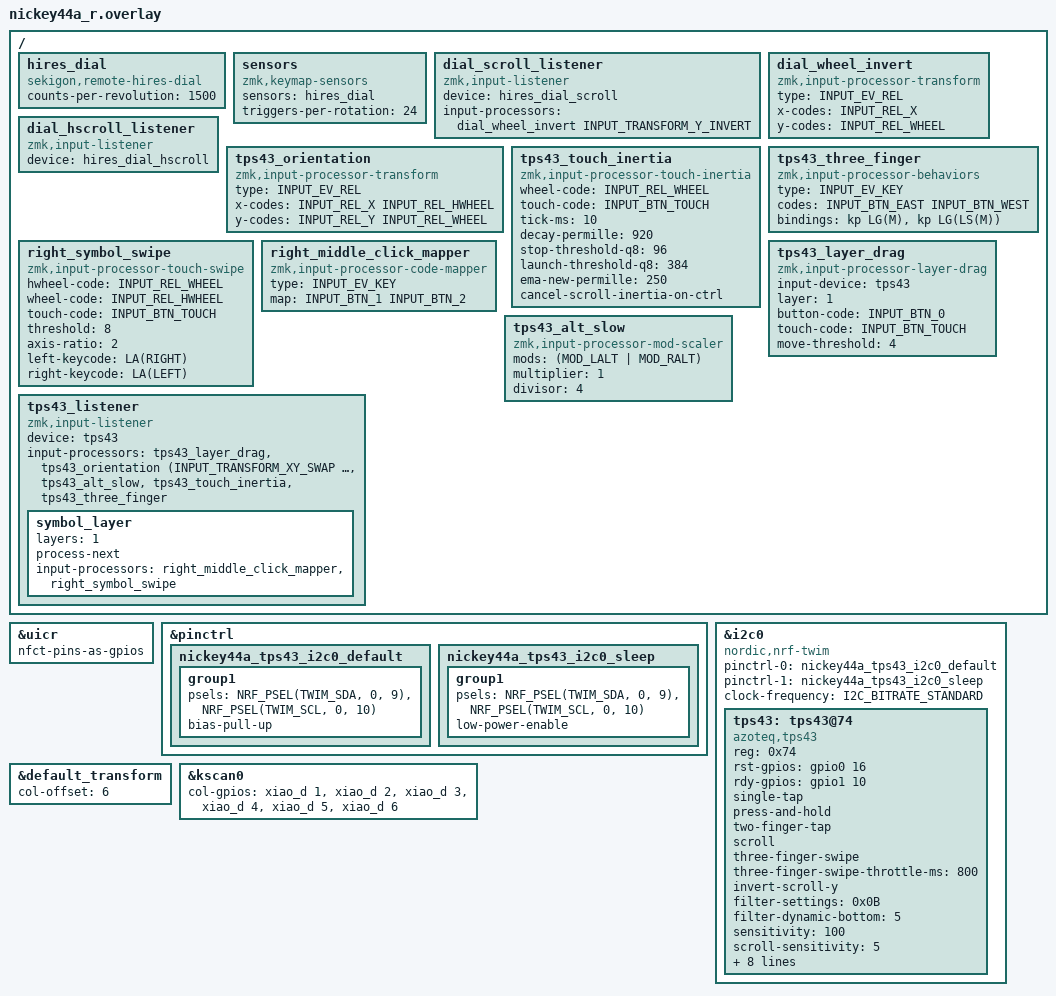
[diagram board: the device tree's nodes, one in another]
#include "nickey44a.dtsi"
#include <input/processors.dtsi>
#include <dt-bindings/pinctrl/nrf-pinctrl.h>
#include <dt-bindings/zmk/input_transform.h>
#include <dt-bindings/zmk/keys.h>
#include <zephyr/dt-bindings/input/input-event-codes.h>

/*
 * TPS43 FPC breakout wiring:
 *   SDA = XIAO NFC1/P0.09
 *   SCL = XIAO NFC2/P0.10
 *   RDY = XIAO P1.10
 *   NRST = XIAO P0.16
 */

&uicr {
    nfct-pins-as-gpios;
};

&pinctrl {
    nickey44a_tps43_i2c0_default: nickey44a_tps43_i2c0_default {
        group1 {
            psels = <NRF_PSEL(TWIM_SDA, 0, 9)>,
                    <NRF_PSEL(TWIM_SCL, 0, 10)>;
            /* The TPS43 breakout has no I2C pull-up resistors. */
            bias-pull-up;
        };
    };

    nickey44a_tps43_i2c0_sleep: nickey44a_tps43_i2c0_sleep {
        group1 {
            psels = <NRF_PSEL(TWIM_SDA, 0, 9)>,
                    <NRF_PSEL(TWIM_SCL, 0, 10)>;
            low-power-enable;
        };
    };
};

/ {
    /* Left-half high-resolution dial (sekigon hires-dial-module). The real
     * PAT9125 sensor sits on the left peripheral; this virtual node receives
     * its rotation over the split link. counts-per-revolution must match the
     * left overlay. */
    hires_dial: hires_dial {
        compatible = "sekigon,remote-hires-dial";
        counts-per-revolution = <1500>;
    };

    sensors: sensors {
        compatible = "zmk,keymap-sensors";
        sensors = <&hires_dial>;
        /* Key-sending layers (FUNC_NUM volume, ARROW tab switch): 24 steps per turn. */
        triggers-per-rotation = <24>;
    };

    /* BASE: dial = vertical wheel. The scroll behavior reports on its own
     * device; this listener sends it to the host. Clockwise (positive counts)
     * becomes a negative wheel = scroll down. */
    dial_scroll_listener: dial_scroll_listener {
        compatible = "zmk,input-listener";
        device = <&hires_dial_scroll>;
        input-processors = <&dial_wheel_invert INPUT_TRANSFORM_Y_INVERT>;
    };

    dial_wheel_invert: dial_wheel_invert {
        compatible = "zmk,input-processor-transform";
        #input-processor-cells = <1>;
        type = <INPUT_EV_REL>;
        x-codes = <INPUT_REL_X>;
        y-codes = <INPUT_REL_WHEEL>;
    };

    /* SYMBOL: dial = horizontal wheel. Clockwise (positive counts) is a
     * positive HWHEEL = scroll right. */
    dial_hscroll_listener: dial_hscroll_listener {
        compatible = "zmk,input-listener";
        device = <&hires_dial_hscroll>;
    };

    tps43_orientation: tps43_orientation {
        compatible = "zmk,input-processor-transform";
        #input-processor-cells = <1>;
        type = <INPUT_EV_REL>;
        x-codes = <INPUT_REL_X INPUT_REL_HWHEEL>;
        y-codes = <INPUT_REL_Y INPUT_REL_WHEEL>;
    };

    tps43_touch_inertia: tps43_touch_inertia {
        compatible = "zmk,input-processor-touch-inertia";
        #input-processor-cells = <0>;
        wheel-code = <INPUT_REL_WHEEL>;
        touch-code = <INPUT_BTN_TOUCH>;
        tick-ms = <10>;
        decay-permille = <920>;
        stop-threshold-q8 = <96>;
        launch-threshold-q8 = <384>;
        ema-new-permille = <250>;
        cancel-scroll-inertia-on-ctrl;
    };

    /* Right pad three-finger swipe. The driver reports it in controller
     * coordinates, before the orientation transform below: physical up is
     * BTN_EAST and physical down is BTN_WEST. Left/right are unmapped. */
    tps43_three_finger: tps43_three_finger {
        compatible = "zmk,input-processor-behaviors";
        #input-processor-cells = <0>;
        type = <INPUT_EV_KEY>;
        codes = <INPUT_BTN_EAST INPUT_BTN_WEST>;
        bindings = <&kp LG(M)>, <&kp LG(LS(M))>;
    };

    /* Used only while SYMBOL is held (see symbol_layer below). Layer
     * overrides run BEFORE tps43_orientation, so this sees the raw controller
     * axes: physical left/right is raw WHEEL and physical up/down is raw
     * HWHEEL. A physical right swipe is a positive raw WHEEL.
     * Right swipe = back (Alt+Left), left swipe = forward (Alt+Right). */
    right_symbol_swipe: right_symbol_swipe {
        compatible = "zmk,input-processor-touch-swipe";
        #input-processor-cells = <0>;
        hwheel-code = <INPUT_REL_WHEEL>;
        wheel-code = <INPUT_REL_HWHEEL>;
        touch-code = <INPUT_BTN_TOUCH>;
        threshold = <8>;
        axis-ratio = <2>;
        left-keycode = <LA(RIGHT)>;
        right-keycode = <LA(LEFT)>;
    };

    right_middle_click_mapper: right_middle_click_mapper {
        compatible = "zmk,input-processor-code-mapper";
        #input-processor-cells = <0>;
        type = <INPUT_EV_KEY>;
        map = <INPUT_BTN_1 INPUT_BTN_2>;
    };

    /* SYMBOL (layer 1) held: once the finger moves, hold the left button
     * until SYMBOL is released, even across finger lifts (drag). Taps and
     * two-finger taps are unaffected. */
    tps43_layer_drag: tps43_layer_drag {
        compatible = "zmk,input-processor-layer-drag";
        #input-processor-cells = <0>;
        input-device = <&tps43>;
        layer = <1>;
        button-code = <INPUT_BTN_0>;
        touch-code = <INPUT_BTN_TOUCH>;
        move-threshold = <4>;
    };

    /* Alt held: precise cursor, 1/4 of normal movement. */
    tps43_alt_slow: tps43_alt_slow {
        compatible = "zmk,input-processor-mod-scaler";
        #input-processor-cells = <0>;
        mods = <(MOD_LALT | MOD_RALT)>;
        multiplier = <1>;
        divisor = <4>;
    };

    tps43_listener: tps43_listener {
        compatible = "zmk,input-listener";
        device = <&tps43>;
        /* Correct the measured controller output: left -> down, down -> left. */
        input-processors = <&tps43_layer_drag>,
                           <&tps43_orientation (INPUT_TRANSFORM_XY_SWAP |
                                             INPUT_TRANSFORM_X_INVERT |
                                             INPUT_TRANSFORM_Y_INVERT)>,
                           <&tps43_alt_slow>, <&tps43_touch_inertia>,
                           <&tps43_three_finger>;

        symbol_layer {
            layers = <1>;
            process-next;
            /* Layer 1: the two-finger tap becomes a middle click instead of a
             * right click, and a two-finger left/right swipe is back/forward
             * instead of horizontal scroll (the drag itself is tps43_layer_drag). */
            input-processors = <&right_middle_click_mapper>, <&right_symbol_swipe>;
        };
    };
};

&i2c0 {
    status = "okay";
    compatible = "nordic,nrf-twim";
    pinctrl-0 = <&nickey44a_tps43_i2c0_default>;
    pinctrl-1 = <&nickey44a_tps43_i2c0_sleep>;
    pinctrl-names = "default", "sleep";
    clock-frequency = <I2C_BITRATE_STANDARD>;
    #address-cells = <1>;
    #size-cells = <0>;

    tps43: tps43@74 {
        compatible = "azoteq,tps43";
        reg = <0x74>;
        rst-gpios = <&gpio0 16 GPIO_ACTIVE_HIGH>;
        rdy-gpios = <&gpio1 10 GPIO_ACTIVE_HIGH>;

        single-tap;
        /* Keep the TPS43 press-and-hold gesture enabled: with it disabled the
         * cursor lagged on some hosts (seen in A/B tests). The 10 s hold time
         * means it effectively never triggers a long-press drag. */
        press-and-hold;
        two-finger-tap;
        scroll;
        /* Three-finger swipe: up/down = minimize/restore all windows. */
        three-finger-swipe;
        /* One action per swipe: ignore repeats within 0.8 s. */
        three-finger-swipe-throttle-ms = <800>;
        /* The listener swaps axes, so driver X controls host vertical scrolling. */
        invert-scroll-y;

        filter-settings = <0x0B>;
        filter-dynamic-bottom = <5>;
        sensitivity = <100>;
        scroll-sensitivity = <5>;
        hold-time = <10000>;
        enable-power-management;
        /* Faster first-touch response: keep idle/low-power scan intervals short.
         * Costs some battery while the keyboard is awake. */
        report-rate-idle-touch = <10>;
        report-rate-idle = <10>;
        report-rate-lp1 = <20>;
        report-rate-lp2 = <40>;
        /* Controller settings used when the listener's correction was measured. */
        switch-xy;
        invert-x;
    };
};

&default_transform {
    col-offset = <6>;
};

&kscan0 {
        col-gpios
            = <&xiao_d 1 GPIO_ACTIVE_HIGH>
            , <&xiao_d 2 GPIO_ACTIVE_HIGH>
            , <&xiao_d 3 GPIO_ACTIVE_HIGH>
            , <&xiao_d 4 GPIO_ACTIVE_HIGH>
            , <&xiao_d 5 GPIO_ACTIVE_HIGH>
            , <&xiao_d 6 GPIO_ACTIVE_HIGH>
            ;
};
